# SKEAZN642 register map
File version: 1.6
Registers are 8-bit, read-write, reset 0x0 unless marked. A register's access mark holds for its fields unless they carry their own. Offsets are from the block's base; [hi:lo] are bit positions.

## SIM — System Integration Module
Base 0x40048000; register names take the prefix SIM_
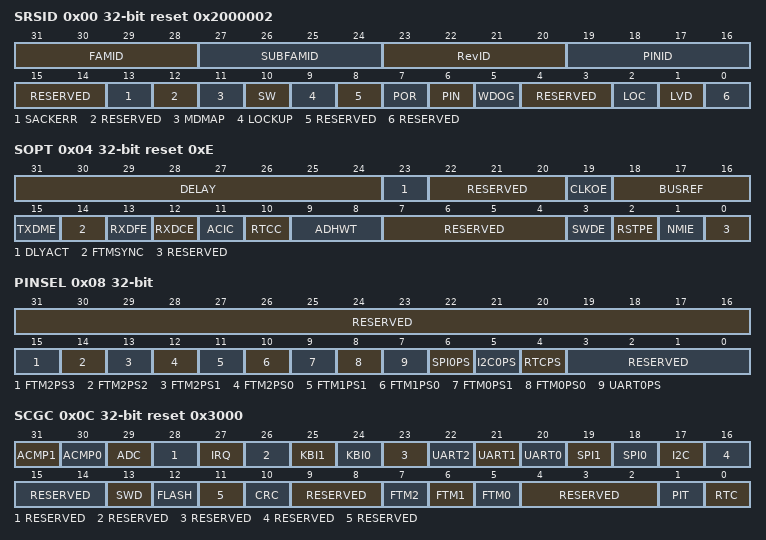
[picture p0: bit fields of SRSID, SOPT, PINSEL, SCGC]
0x00 SRSID 32-bit ro reset 0x2000002 — System Reset Status and ID Register
  [31:28] FAMID — Kinetis family ID
    0=KE0x family
  [27:24] SUBFAMID — Kinetis sub-family ID
    2=KEx2 sub-family
  [23:20] RevID — Device Revision Number
  [19:16] PINID — Device Pin ID
    0=8-pin; 1=16-pin; 2=20-pin; 3=24-pin; 4=32-pin; 5=44-pin; 6=48-pin; 7=64-pin; 8=80-pin; 10=100-pin
  [15:14] RESERVED
  [13] SACKERR — Stop Mode Acknowledge Error Reset
    0=Reset is not caused by peripheral failure to acknowledge attempt to enter Stop mode; 1=Reset is caused by peripheral failure to acknowledge attempt to enter Stop mode
  [12] RESERVED
  [11] MDMAP — MDM-AP System Reset Request
    0=Reset is not caused by host debugger system setting of the System Reset Request bit; 1=Reset is caused by host debugger system setting of the System Reset Request bit
  [10] SW — Software
    0=Reset is not caused by software setting of SYSRESETREQ bit; 1=Reset caused by software setting of SYSRESETREQ bit
  [9] LOCKUP — Core Lockup
    0=Reset is not caused by core LOCKUP event; 1=Reset is caused by core LOCKUP event
  [8] RESERVED
  [7] POR — Power-On Reset
    0=Reset not caused by POR; 1=POR caused reset
  [6] PIN — External Reset Pin
    0=Reset is not caused by external reset pin; 1=Reset came from external reset pin
  [5] WDOG — Watchdog (WDOG)
    0=Reset is not caused by WDOG timeout; 1=Reset is caused by WDOG timeout
  [4:3] RESERVED
  [2] LOC — Internal Clock Source Module Reset
    0=Reset is not caused by the ICS module; 1=Reset is caused by the ICS module
  [1] LVD — Low Voltage Detect
    0=Reset is not caused by LVD trip or POR; 1=Reset is caused by LVD trip or POR
  [0] RESERVED
0x04 SOPT 32-bit reset 0xE — System Options Register
  [31:24] DELAY — FTM2 Trigger Delay
  [23] DLYACT ro — FTM2 Trigger Delay Active
    0=The delay is inactive; 1=The delay is active
  [22:20] RESERVED ro
  [19] CLKOE — Bus Clock Output Enable
    0=Bus clock output is disabled on PTH2; 1=Bus clock output is enabled on PTH2
  [18:16] BUSREF — BUS Clock Output select
    0=Bus; 1=Bus divided by 2; 2=Bus divided by 4; 3=Bus divided by 8; 4=Bus divided by 16; 5=Bus divided by 32; 6=Bus divided by 64; 7=Bus divided by 128
  [15] TXDME — UART0_TX Modulation Select
    0=UART0_TX output is connected to pinout directly; 1=UART0_TX output is modulated by FTM0 channel 0 before mapped to pinout
  [14] FTMSYNC wo — FTM2 Synchronization Select
    0=No synchronization triggered; 1=Generates a PWM synchronization trigger to the FTM2 modules
  [13] RXDFE — UART0_RX Filter Select
    0=UART0_RX input signal is connected to UART0 module directly; 1=UART0_RX input signal is filtered by ACMP, then injected to UART0
  [12] RXDCE — UART0_RX Capture Select
    0=UART0_RX input signal is connected to the UART0 module only; 1=UART0_RX input signal is connected to the UART0 module and FTM0 channel 1
  [11] ACIC — Analog Comparator to Input Capture Enable
    0=ACMP0 output is not connected to FTM1 input channel 0; 1=ACMP0 output is connected to FTM1 input channel 0
  [10] RTCC — Real-Time Counter Capture
    0=RTC overflow is not connected to FTM1 input channel 1; 1=RTC overflow is connected to FTM1 input channel 1
  [9:8] ADHWT — ADC Hardware Trigger Source
    0=RTC overflow as the ADC hardware trigger; 1=PIT overflow as the ADC hardware trigger; 2=FTM2 init trigger with 8-bit programmable delay; 3=FTM2 match trigger with 8-bit programmable delay
  [7:4] RESERVED ro
  [3] SWDE — Single Wire Debug Port Pin Enable
    0=PTA4/ACMP0_OUT/SWD_DIO as PTA4 or ACMP0_OUT function, PTC4/RTCO/FTM1_CH0/ACMP0_IN2/SWD_CLK as PTC4, RTCO, FTM1_CH0, or ACMP0_IN2 function; 1=PTA4/ACMP0_OUT/SWD_DIO as SWD_DIO function, PTC4/RTCO/FTM1CH0/ACMP0_IN2/SWD_CLK as SWD_CLK function
  [2] RSTPE — RESET Pin Enable
    0=PTA5/IRQ/FTM0_CLK/RESET pin functions as PTA5, IRQ, or FTM0_CLK; 1=PTA5/IRQ/FTM0_CLK/RESET pin functions as RESET
  [1] NMIE — NMI Pin Enable
    0=PTB4/FTM2_CH4/SPI0_MISO/NMI/ACMP1_IN2 pin functions as PTB4, FTM2_CH4, SPI0_MISO, or ACMP1_IN2; 1=PTB4/FTM2_CH4/SPI0_MISO/NMI/ACMP1_IN2 pin functions as NMI
  [0] RESERVED ro
0x08 PINSEL 32-bit — Pin Selection Register
  [31:16] RESERVED ro
  [15] FTM2PS3 — FTM2[3] Port Pin Select
    0=FTM2[3] channels are mapped on PTC3; 1=FTM2[3] channels are mapped on PTD1
  [14] FTM2PS2 — FTM2[2] Port Pin Select
    0=FTM2[2] channels are mapped on PTC2; 1=FTM2[2] channels are mapped on PTD0
  [13] FTM2PS1 — FTM2[1] Port Pin Select
    0=FTM2[1] channels are mapped on PTC1; 1=FTM2[1] channels are mapped on PTH1
  [12] FTM2PS0 — FTM2[0] Port Pin Select
    0=FTM2[0] channels are mapped on PTC0; 1=FTM2[0] channels are mapped on PTH0
  [11] FTM1PS1 — FTM1[1] Port Pin Select
    0=FTM1[1] channels are mapped on PTC5; 1=FTM1[1] channels are mapped on PTE7
  [10] FTM1PS0 — FTM1[0] Port Pin Select
    0=FTM1[0] channels are mapped on PTC4; 1=FTM1[0] channels are mapped on PTH2
  [9] FTM0PS1 — FTM0[1] Port Pin Select
    0=FTM0[1] channels are mapped on PTA1; 1=FTM0[1] channels are mapped on PTB3
  [8] FTM0PS0 — FTM0[0] Port Pin Select
    0=FTM0[0] channels are mapped on PTA0; 1=FTM0[0] channels are mapped on PTB2
  [7] UART0PS — UART0 Pin Select
    0=UART0_RX and UART0_TX are mapped on PTB0 and PTB1; 1=UART0_RX and UART0_TX are mapped on PTA2 and PTA3
  [6] SPI0PS — SPI0 Pin Select
    0=SPI0_SCK, SPI0_MOSI, SPI0_MISO, and SPI0_PCS0 are mapped on PTB2, PTB3, PTB4, and PTB5; 1=SPI0_SCK, SPI0_MOSI, SPI0_MISO, and SPI0_PCS0 are mapped on PTE0, PTE1, PTE2, and PTE3
  [5] I2C0PS — I2C0 Port Pin Select
    0=I2C0_SCL and I2C0_SDA are mapped on PTA3 and PTA2, respectively; 1=I2C0_SCL and I2C0_SDA are mapped on PTB7 and PTB6, respectively
  [4] RTCPS — RTCO Pin Select
    0=RTCO is mapped on PTC4; 1=RTCO is mapped on PTC5
  [3:0] RESERVED ro
0x0C SCGC 32-bit reset 0x3000 — System Clock Gating Control Register
  [31] ACMP1 — ACMP1 Clock Gate Control
    0=Bus clock to the ACMP1 module is disabled; 1=Bus clock to the ACMP1 module is enabled
  [30] ACMP0 — ACMP0 Clock Gate Control
    0=Bus clock to the ACMP0 module is disabled; 1=Bus clock to the ACMP0 module is enabled
  [29] ADC — ADC Clock Gate Control
    0=Bus clock to the ADC module is disabled; 1=Bus clock to the ADC module is enabled
  [28] RESERVED ro
  [27] IRQ — IRQ Clock Gate Control
    0=Bus clock to the IRQ module is disabled; 1=Bus clock to the IRQ module is enabled
  [26] RESERVED ro
  [25] KBI1 — KBI1 Clock Gate Control
    0=Bus clock to the KBI1 module is disabled; 1=Bus clock to the KBI1 module is enabled
  [24] KBI0 — KBI0 Clock Gate Control
    0=Bus clock to the KBI0 module is disabled; 1=Bus clock to the KBI0 module is enabled
  [23] RESERVED ro
  [22] UART2 — UART2 Clock Gate Control
    0=Bus clock to the UART2 module is disabled; 1=Bus clock to the UART2 module is enabled
  [21] UART1 — UART1 Clock Gate Control
    0=Bus clock to the UART1 module is disabled; 1=Bus clock to the UART1 module is enabled
  [20] UART0 — UART0 Clock Gate Control
    0=Bus clock to the UART0 module is disabled; 1=Bus clock to the UART0 module is enabled
  [19] SPI1 — SPI1 Clock Gate Control
    0=Bus clock to the SPI1 module is disabled; 1=Bus clock to the SPI1 module is enabled
  [18] SPI0 — SPI0 Clock Gate Control
    0=Bus clock to the SPI0 module is disabled; 1=Bus clock to the SPI0 module is enabled
  [17] I2C — I2C Clock Gate Control
    0=Bus clock to the IIC module is disabled; 1=Bus clock to the IIC module is enabled
  [16:14] RESERVED ro
  [13] SWD — SWD (single wire debugger) Clock Gate Control
    0=Bus clock to the SWD module is disabled; 1=Bus clock to the SWD module is enabled
  [12] FLASH — Flash Clock Gate Control
    0=Bus clock to the flash module is disabled; 1=Bus clock to the flash module is enabled
  [11] RESERVED ro
  [10] CRC — CRC Clock Gate Control
    0=Bus clock to the CRC module is disabled; 1=Bus clock to the CRC module is enabled
  [9:8] RESERVED ro
  [7] FTM2 — FTM2 Clock Gate Control
    0=Bus clock to the FTM2 module is disabled; 1=Bus clock to the FTM2 module is enabled
  [6] FTM1 — FTM1 Clock Gate Control
    0=Bus clock to the FTM1 module is disabled; 1=Bus clock to the FTM1 module is enabled
  [5] FTM0 — FTM0 Clock Gate Control
    0=Bus clock to the FTM0 module is disabled; 1=Bus clock to the FTM0 module is enabled
  [4:2] RESERVED ro
  [1] PIT — PIT Clock Gate Control
    0=Bus clock to the PIT module is disabled; 1=Bus clock to the PIT module is enabled
  [0] RTC — RTC Clock Gate Control
    0=Bus clock to the RTC module is disabled; 1=Bus clock to the RTC module is enabled
0x10 UUIDL 32-bit ro reset not defined — Universally Unique Identifier Low Register
  [31:0] ID — Universally Unique Identifier
0x14 UUIDH 32-bit ro reset not defined — Universally Unique Identifier High Register
  [31:0] ID — Universally Unique Identifier
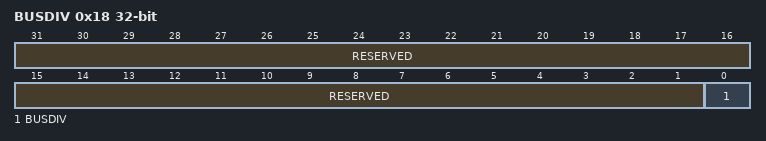
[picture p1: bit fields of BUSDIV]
0x18 BUSDIV 32-bit — BUS Clock Divider Register
  [31:1] RESERVED ro
  [0] BUSDIV — BUS Clock Divider
    0=Bus clock is same as ICSOUTCLK; 1=Bus clock is ICSOUTCLK divided by 2
